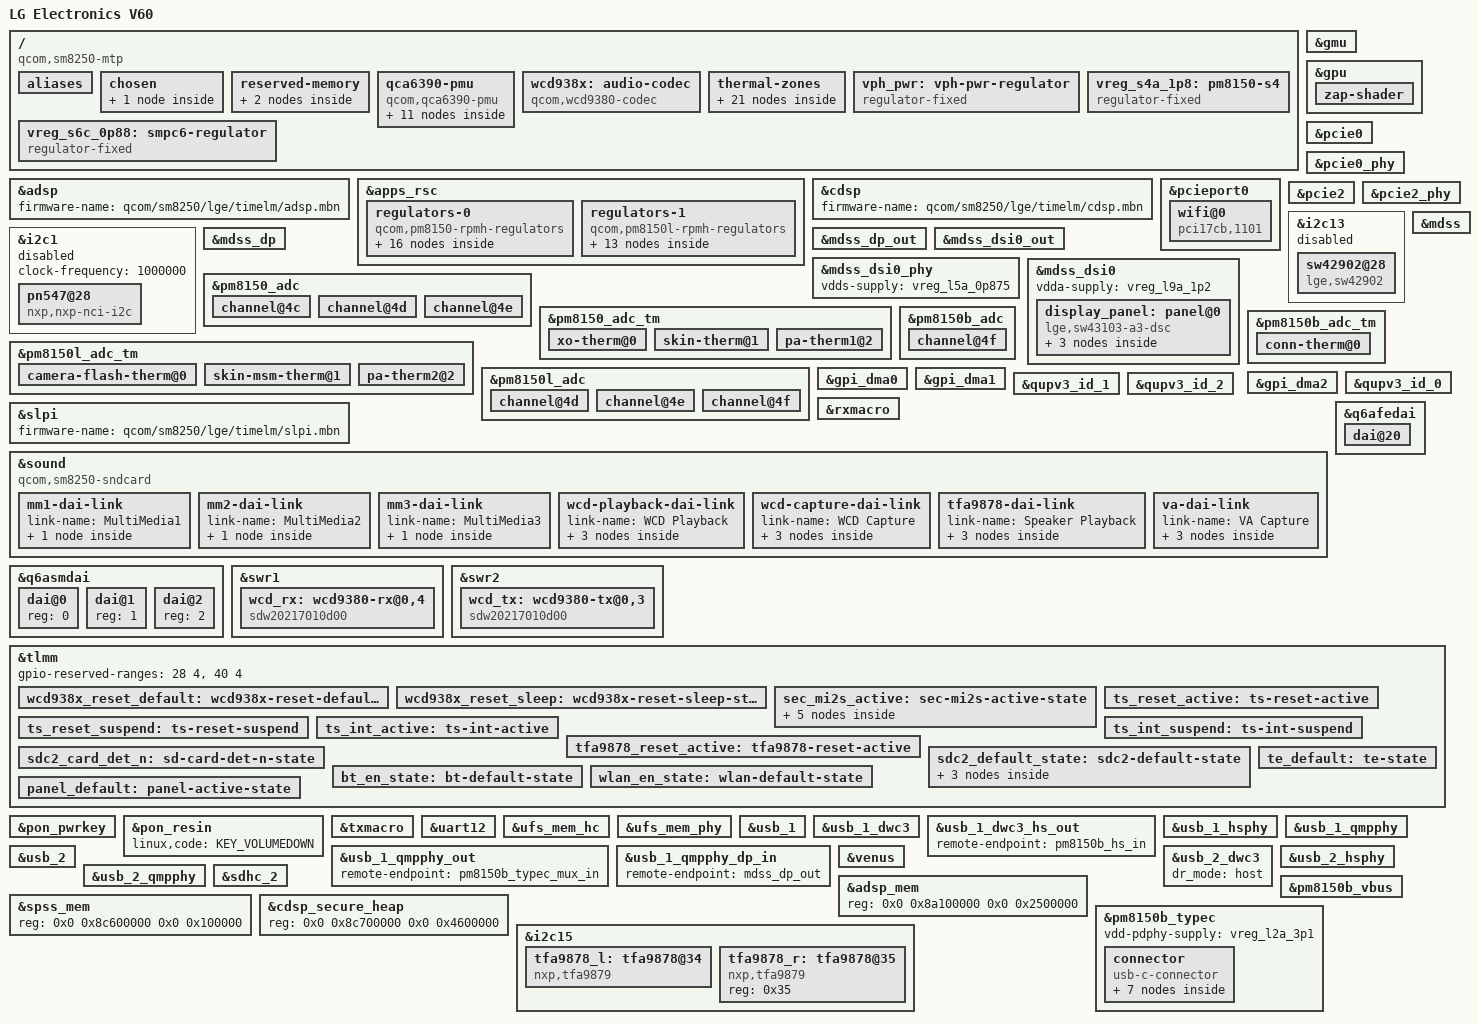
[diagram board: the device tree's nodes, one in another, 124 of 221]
// SPDX-License-Identifier: BSD-3-Clause
/*
 * Copyright (c) 2020, The Linux Foundation. All rights reserved.
 */

/dts-v1/;

#include <dt-bindings/regulator/qcom,rpmh-regulator.h>
#include <dt-bindings/sound/qcom,q6afe.h>
#include <dt-bindings/sound/qcom,q6asm.h>
#include <dt-bindings/usb/pd.h>
#include <dt-bindings/gpio/gpio.h>
#include "sm8250.dtsi"
#include "pm8150.dtsi"
#include "pm8150b.dtsi"
#include "pm8150l.dtsi"
// #include "pm8009.dtsi"
#include "pmk8002.dtsi"
#include "pmx55.dtsi"

/ {
	model = "LG Electronics V60";
	compatible = "qcom,sm8250-mtp", "qcom,sm8250";
	chassis-type = "handset";
	qcom,msm-id = <0x164 0x20001>;
	qcom,board-id = <0xc0008 0x0>;

	aliases {
		serial0 = &uart12;
        display0 = &framebuffer;
	};

	chosen {
		#address-cells = <2>;
		#size-cells = <2>;
		ranges;
		// stdout-path = "serial0:115200n8";
		stdout-path = "display0";
		bootargs = "panic=30 loglevel=7 pd_ignore_unused clk_ignore_unused console=ttyS0,115200 console=tty1 root=/dev/sda27 rw rootfs_part=sda27";

		framebuffer: framebuffer@9c000000 {
			compatible = "simple-framebuffer";
			reg = <0x0 0x9c000000 0x0 0x1200000>;
			width = <1080>;
			height = <2460>;
			stride = <(1080 * 4)>;
			format = "a8r8g8b8";
			/*
			 * That's a lot of clocks, but it's necessary due
			 * to unused clk cleanup & no panel driver yet..
			 */
			// clocks = <&dispcc DISP_CC_MDSS_AHB_CLK>,
			// 	 <&gcc GCC_DISP_HF_AXI_CLK>,
			// 	 <&gcc GCC_DISP_SF_AXI_CLK>,
			// 	 <&dispcc DISP_CC_MDSS_VSYNC_CLK>,
			// 	 <&dispcc DISP_CC_MDSS_MDP_CLK>,
			// 	 <&dispcc DISP_CC_MDSS_BYTE0_CLK>,
			// 	 <&dispcc DISP_CC_MDSS_BYTE0_INTF_CLK>,
			// 	 <&dispcc DISP_CC_MDSS_PCLK0_CLK>,
			// 	 <&dispcc DISP_CC_MDSS_ESC0_CLK>;
			// power-domains = <&dispcc MDSS_GDSC>;
		};
	};

	reserved-memory {
		ramoops_region@b0000000 {
			compatible = "removed-dma-pool";
			no-map;
			reg = <0x0 0xb0000000 0x0 0x300000>;
		};

		cont_splash_region@9c000000 {
			reg = <0x0 0x9c000000 0x0 0x1200000>;
			label = "cont_splash_region";
			no-map;
		};
	};

	qca6390-pmu {
		compatible = "qcom,qca6390-pmu";

		pinctrl-names = "default";
		pinctrl-0 = <&bt_en_state>, <&wlan_en_state>;

		vddaon-supply = <&vreg_s6a_0p95>;
		vddpmu-supply = <&vreg_s6a_0p95>;
		vddrfa0p95-supply = <&vreg_s6a_0p95>;
		vddrfa1p3-supply = <&vreg_s8c_1p3>;
		vddrfa1p9-supply = <&vreg_s5a_1p9>;
		vddpcie1p3-supply = <&vreg_s8c_1p3>;
		vddpcie1p9-supply = <&vreg_s5a_1p9>;
		vddio-supply = <&vreg_s4a_1p8>;

		wlan-enable-gpios = <&tlmm 20 GPIO_ACTIVE_HIGH>;
		bt-enable-gpios = <&tlmm 21 GPIO_ACTIVE_HIGH>;

		regulators {
			vreg_pmu_rfa_cmn: ldo0 {
				regulator-name = "vreg_pmu_rfa_cmn";
			};

			vreg_pmu_aon_0p59: ldo1 {
				regulator-name = "vreg_pmu_aon_0p59";
			};

			vreg_pmu_wlcx_0p8: ldo2 {
				regulator-name = "vreg_pmu_wlcx_0p8";
			};

			vreg_pmu_wlmx_0p85: ldo3 {
				regulator-name = "vreg_pmu_wlmx_0p85";
			};

			vreg_pmu_btcmx_0p85: ldo4 {
				regulator-name = "vreg_pmu_btcmx_0p85";
			};

			vreg_pmu_rfa_0p8: ldo5 {
				regulator-name = "vreg_pmu_rfa_0p8";
			};

			vreg_pmu_rfa_1p2: ldo6 {
				regulator-name = "vreg_pmu_rfa_1p2";
			};

			vreg_pmu_rfa_1p7: ldo7 {
				regulator-name = "vreg_pmu_rfa_1p7";
			};

			vreg_pmu_pcie_0p9: ldo8 {
				regulator-name = "vreg_pmu_pcie_0p9";
			};

			vreg_pmu_pcie_1p8: ldo9 {
				regulator-name = "vreg_pmu_pcie_1p8";
			};
		};
	};

	wcd938x: audio-codec {
		compatible = "qcom,wcd9380-codec";

		reset-gpios = <&tlmm 32 GPIO_ACTIVE_LOW>;

		vdd-buck-supply = <&vreg_s4a_1p8>;
		vdd-rxtx-supply = <&vreg_s4a_1p8>;
		vdd-io-supply = <&vreg_s4a_1p8>;
		vdd-mic-bias-supply = <&vreg_bob>;

		qcom,micbias1-microvolt = <1800000>;
		qcom,micbias2-microvolt = <1800000>;
		qcom,micbias3-microvolt = <1800000>;
		qcom,micbias4-microvolt = <1800000>;
		qcom,mbhc-buttons-vthreshold-microvolt = <75000 150000 237000 500000 500000 500000 500000 500000>;
		qcom,mbhc-headset-vthreshold-microvolt = <1700000>;
		qcom,mbhc-headphone-vthreshold-microvolt = <50000>;
		qcom,rx-device = <&wcd_rx>;
		qcom,tx-device = <&wcd_tx>;

		#sound-dai-cells = <1>;
	};

	thermal-zones {
		camera-thermal {
			thermal-sensors = <&pm8150l_adc_tm 0>;

			trips {
				active-config0 {
					temperature = <125000>;
					hysteresis = <1000>;
					type = "passive";
				};
			};
		};

		conn-thermal {
			thermal-sensors = <&pm8150b_adc_tm 0>;

			trips {
				active-config0 {
					temperature = <125000>;
					hysteresis = <1000>;
					type = "passive";
				};
			};
		};

		mmw-pa1-thermal {
			thermal-sensors = <&pm8150_adc_tm 2>;

			trips {
				active-config0 {
					temperature = <125000>;
					hysteresis = <1000>;
					type = "passive";
				};
			};
		};

		mmw-pa2-thermal {
			thermal-sensors = <&pm8150l_adc_tm 2>;

			trips {
				active-config0 {
					temperature = <125000>;
					hysteresis = <1000>;
					type = "passive";
				};
			};
		};

		skin-msm-thermal {
			thermal-sensors = <&pm8150l_adc_tm 1>;

			trips {
				active-config0 {
					temperature = <125000>;
					hysteresis = <1000>;
					type = "passive";
				};
			};
		};

		skin-thermal {
			thermal-sensors = <&pm8150_adc_tm 1>;

			trips {
				active-config0 {
					temperature = <125000>;
					hysteresis = <1000>;
					type = "passive";
				};
			};
		};

		xo-thermal {
			thermal-sensors = <&pm8150_adc_tm 0>;

			trips {
				active-config0 {
					temperature = <125000>;
					hysteresis = <1000>;
					type = "passive";
				};
			};
		};
	};

	vph_pwr: vph-pwr-regulator {
		compatible = "regulator-fixed";
		regulator-name = "vph_pwr";
		regulator-min-microvolt = <3700000>;
		regulator-max-microvolt = <3700000>;
	};

	vreg_s4a_1p8: pm8150-s4 {
		compatible = "regulator-fixed";
		regulator-name = "vreg_s4a_1p8";

		regulator-min-microvolt = <1800000>;
		regulator-max-microvolt = <1800000>;

		regulator-always-on;
		regulator-boot-on;

		vin-supply = <&vph_pwr>;
	};

	vreg_s6c_0p88: smpc6-regulator {
		compatible = "regulator-fixed";
		regulator-name = "vreg_s6c_0p88";

		regulator-min-microvolt = <880000>;
		regulator-max-microvolt = <880000>;
		regulator-always-on;
		vin-supply = <&vph_pwr>;
	};
};

&adsp {
	status = "okay";
	firmware-name = "qcom/sm8250/lge/timelm/adsp.mbn";
};

&apps_rsc {
	regulators-0 {
		compatible = "qcom,pm8150-rpmh-regulators";
		qcom,pmic-id = "a";

		vdd-s1-supply = <&vph_pwr>;
		vdd-s2-supply = <&vph_pwr>;
		vdd-s3-supply = <&vph_pwr>;
		vdd-s4-supply = <&vph_pwr>;
		vdd-s5-supply = <&vph_pwr>;
		vdd-s6-supply = <&vph_pwr>;
		vdd-s7-supply = <&vph_pwr>;
		vdd-s8-supply = <&vph_pwr>;
		vdd-s9-supply = <&vph_pwr>;
		vdd-s10-supply = <&vph_pwr>;
		vdd-l1-l8-l11-supply = <&vreg_s6c_0p88>;
		vdd-l2-l10-supply = <&vreg_bob>;
		vdd-l3-l4-l5-l18-supply = <&vreg_s6a_0p95>;
		vdd-l6-l9-supply = <&vreg_s8c_1p3>;
		vdd-l7-l12-l14-l15-supply = <&vreg_s5a_1p9>;
		vdd-l13-l16-l17-supply = <&vreg_bob>;

		vreg_s5a_1p9: smps5 {
			regulator-name = "vreg_s5a_1p9";
			regulator-min-microvolt = <1904000>;
			regulator-max-microvolt = <2000000>;
			regulator-initial-mode = <RPMH_REGULATOR_MODE_HPM>;
		};

		vreg_s6a_0p95: smps6 {
			regulator-name = "vreg_s6a_0p95";
			regulator-min-microvolt = <920000>;
			regulator-max-microvolt = <1128000>;
			regulator-initial-mode = <RPMH_REGULATOR_MODE_HPM>;
		};

		vreg_l2a_3p1: ldo2 {
			regulator-name = "vreg_l2a_3p1";
			regulator-min-microvolt = <3072000>;
			regulator-max-microvolt = <3072000>;
			regulator-initial-mode = <RPMH_REGULATOR_MODE_HPM>;
		};

		vreg_l3a_0p9: ldo3 {
			regulator-name = "vreg_l3a_0p9";
			regulator-min-microvolt = <928000>;
			regulator-max-microvolt = <932000>;
			regulator-initial-mode = <RPMH_REGULATOR_MODE_HPM>;
		};

		vreg_l5a_0p875: ldo5 {
			regulator-name = "vreg_l5a_0p875";
			regulator-min-microvolt = <880000>;
			regulator-max-microvolt = <880000>;
			regulator-initial-mode = <RPMH_REGULATOR_MODE_HPM>;
		};

		vreg_l6a_1p2: ldo6 {
			regulator-name = "vreg_l6a_1p2";
			regulator-min-microvolt = <1200000>;
			regulator-max-microvolt = <1200000>;
			regulator-initial-mode = <RPMH_REGULATOR_MODE_HPM>;
		};

		vreg_l7a_1p7: ldo7 {
			regulator-name = "vreg_l7a_1p7";
			regulator-min-microvolt = <1704000>;
			regulator-max-microvolt = <1800000>;
			regulator-initial-mode = <RPMH_REGULATOR_MODE_HPM>;
		};

		vreg_l9a_1p2: ldo9 {
			regulator-name = "vreg_l9a_1p2";
			regulator-min-microvolt = <1200000>;
			regulator-max-microvolt = <1200000>;
			regulator-initial-mode = <RPMH_REGULATOR_MODE_HPM>;
		};

		vreg_l10a_1p8: ldo10 {
			regulator-name = "vreg_l10a_1p8";
			regulator-min-microvolt = <1800000>;
			regulator-max-microvolt = <1800000>;
			regulator-initial-mode = <RPMH_REGULATOR_MODE_HPM>;
		};

		vreg_l12a_1p8: ldo12 {
			regulator-name = "vreg_l12a_1p8";
			regulator-min-microvolt = <1800000>;
			regulator-max-microvolt = <1800000>;
			regulator-initial-mode = <RPMH_REGULATOR_MODE_HPM>;
		};

		vreg_l13a_ts_3p0: ldo13 {
			regulator-name = "vreg_l13a_ts_3p0";
			regulator-min-microvolt = <3008000>;
			regulator-max-microvolt = <3008000>;
			regulator-initial-mode = <RPMH_REGULATOR_MODE_HPM>;
		};

		vreg_l14a_1p8: ldo14 {
			regulator-name = "vreg_l14a_1p8";
			regulator-min-microvolt = <1800000>;
			regulator-max-microvolt = <1880000>;
			regulator-initial-mode = <RPMH_REGULATOR_MODE_HPM>;
		};

		vreg_l15a_11ad_io_1p8: ldo15 {
			regulator-name = "vreg_l15a_11ad_io_1p8";
			regulator-min-microvolt = <1800000>;
			regulator-max-microvolt = <1800000>;
			regulator-initial-mode = <RPMH_REGULATOR_MODE_HPM>;
		};

		vreg_l16a_2p7: ldo16 {
			regulator-name = "vreg_l16a_2p7";
			regulator-min-microvolt = <2704000>;
			regulator-max-microvolt = <2960000>;
			regulator-initial-mode = <RPMH_REGULATOR_MODE_HPM>;
		};

		vreg_l17a_3p0: ldo17 {
			regulator-name = "vreg_l17a_3p0";
			regulator-min-microvolt = <2856000>;
			regulator-max-microvolt = <3008000>;
			regulator-initial-mode = <RPMH_REGULATOR_MODE_HPM>;
		};

		vreg_l18a_0p9: ldo18 {
			regulator-name = "vreg_l18a_0p9";
			regulator-min-microvolt = <912000>;
			regulator-max-microvolt = <912000>;
			regulator-initial-mode = <RPMH_REGULATOR_MODE_HPM>;
		};
	};

	regulators-1 {
		compatible = "qcom,pm8150l-rpmh-regulators";
		qcom,pmic-id = "c";

		vdd-s1-supply = <&vph_pwr>;
		vdd-s2-supply = <&vph_pwr>;
		vdd-s3-supply = <&vph_pwr>;
		vdd-s4-supply = <&vph_pwr>;
		vdd-s5-supply = <&vph_pwr>;
		vdd-s6-supply = <&vph_pwr>;
		vdd-s7-supply = <&vph_pwr>;
		vdd-s8-supply = <&vph_pwr>;
		vdd-l1-l8-supply = <&vreg_s4a_1p8>;
		vdd-l2-l3-supply = <&vreg_s8c_1p3>;
		vdd-l4-l5-l6-supply = <&vreg_bob>;
		vdd-l7-l11-supply = <&vreg_bob>;
		vdd-l9-l10-supply = <&vreg_bob>;
		vdd-bob-supply = <&vph_pwr>;

		vreg_bob: bob {
			regulator-name = "vreg_bob";
			regulator-min-microvolt = <3008000>;
			regulator-max-microvolt = <4000000>;
			regulator-initial-mode = <RPMH_REGULATOR_MODE_AUTO>;
		};

		vreg_s8c_1p3: smps8 {
			regulator-name = "vreg_s8c_1p3";
			regulator-min-microvolt = <1352000>;
			regulator-max-microvolt = <1352000>;
			regulator-initial-mode = <RPMH_REGULATOR_MODE_HPM>;
		};

		vreg_l1c_1p8: ldo1 {
			regulator-name = "vreg_l1c_1p8";
			regulator-min-microvolt = <1800000>;
			regulator-max-microvolt = <1800000>;
			regulator-initial-mode = <RPMH_REGULATOR_MODE_HPM>;
		};

		vreg_l2c_1p2: ldo2 {
			regulator-name = "vreg_l2c_1p2";
			regulator-min-microvolt = <1200000>;
			regulator-max-microvolt = <1200000>;
			regulator-initial-mode = <RPMH_REGULATOR_MODE_HPM>;
		};

		vreg_l3c_0p92: ldo3 {
			regulator-name = "vreg_l3c_0p92";
			regulator-min-microvolt = <920000>;
			regulator-max-microvolt = <920000>;
			regulator-initial-mode = <RPMH_REGULATOR_MODE_HPM>;
		};

		vreg_l4c_1p7: ldo4 {
			regulator-name = "vreg_l4c_1p7";
			regulator-min-microvolt = <1704000>;
			regulator-max-microvolt = <2928000>;
			regulator-initial-mode = <RPMH_REGULATOR_MODE_HPM>;
		};

		vreg_l5c_1p8: ldo5 {
			regulator-name = "vreg_l5c_1p8";
			regulator-min-microvolt = <1800000>;
			regulator-max-microvolt = <2928000>;
			regulator-initial-mode = <RPMH_REGULATOR_MODE_HPM>;
		};

		vreg_l6c_2p9: ldo6 {
			regulator-name = "vreg_l6c_2p9";
			regulator-min-microvolt = <1800000>;
			regulator-max-microvolt = <2960000>;
			regulator-initial-mode = <RPMH_REGULATOR_MODE_HPM>;
		};

		vreg_l7c_cam_vcm0_2p85: ldo7 {
			regulator-name = "vreg_l7c_cam_vcm0_2p85";
			regulator-min-microvolt = <2856000>;
			regulator-max-microvolt = <3104000>;
			regulator-initial-mode = <RPMH_REGULATOR_MODE_HPM>;
		};

		vreg_l8c_1p8: ldo8 {
			regulator-name = "vreg_l8c_1p8";
			regulator-min-microvolt = <1800000>;
			regulator-max-microvolt = <1800000>;
			regulator-initial-mode = <RPMH_REGULATOR_MODE_HPM>;
		};

		vreg_l9c_2p9: ldo9 {
			regulator-name = "vreg_l9c_2p9";
			regulator-min-microvolt = <2704000>;
			regulator-max-microvolt = <2960000>;
			regulator-initial-mode = <RPMH_REGULATOR_MODE_HPM>;
		};

		vreg_l10c_3p0: ldo10 {
			regulator-name = "vreg_l10c_3p0";
			regulator-min-microvolt = <3000000>;
			regulator-max-microvolt = <3000000>;
			regulator-initial-mode = <RPMH_REGULATOR_MODE_HPM>;
		};

		vreg_l11c_3p3: ldo11 {
			regulator-name = "vreg_l11c_3p3";
			regulator-min-microvolt = <3000000>;
			regulator-max-microvolt = <3312000>;
			regulator-initial-mode = <RPMH_REGULATOR_MODE_HPM>;
		};
	};
};

&cdsp {
	status = "okay";
	firmware-name = "qcom/sm8250/lge/timelm/cdsp.mbn";
};

&gmu {
	status = "okay";
};

&gpu {
	status = "okay";

	zap-shader {
		memory-region = <&gpu_mem>;
		firmware-name = "qcom/sm8250/lge/timelm/a650_zap.mbn";
	};
};

&pcie0 {
	status = "okay";
};

&pcie0_phy {
	status = "okay";
	vdda-phy-supply = <&vreg_l5a_0p875>;
	vdda-pll-supply = <&vreg_l9a_1p2>;
};

&pcieport0 {
	wifi@0 {
		compatible = "pci17cb,1101";
		reg = <0x10000 0x0 0x0 0x0 0x0>;

		vddrfacmn-supply = <&vreg_pmu_rfa_cmn>;
		vddaon-supply = <&vreg_pmu_aon_0p59>;
		vddwlcx-supply = <&vreg_pmu_wlcx_0p8>;
		vddwlmx-supply = <&vreg_pmu_wlmx_0p85>;
		vddrfa0p8-supply = <&vreg_pmu_rfa_0p8>;
		vddrfa1p2-supply = <&vreg_pmu_rfa_1p2>;
		vddrfa1p7-supply = <&vreg_pmu_rfa_1p7>;
		vddpcie0p9-supply = <&vreg_pmu_pcie_0p9>;
		vddpcie1p8-supply = <&vreg_pmu_pcie_1p8>;
	};
};

&pcie2 {
	status = "okay";
};

&pcie2_phy {
	status = "okay";
	vdda-phy-supply = <&vreg_l5a_0p875>;
	vdda-pll-supply = <&vreg_l9a_1p2>;
};

&i2c1 {
	status = "disabled";
	clock-frequency = <1000000>;
	
	pn547@28 {
		compatible = "nxp,nxp-nci-i2c";
		status = "okay";
		reg = <0x28>;
		interrupt-parent = <&tlmm>;
		interrupts = <111 IRQ_TYPE_LEVEL_HIGH>;
		enable-gpios = <&tlmm 6 GPIO_ACTIVE_HIGH>;
		firmware-gpios = <&tlmm 110 GPIO_ACTIVE_HIGH>;
	};
};

&i2c13 {
	status = "disabled";
	sw42902@28 {
		compatible = "lge,sw42902";
		reg = <0x28>;
		status = "okay";
		interrupt-parent = <&tlmm>;
		interrupts = <39 0x2008>; /* IRQF_ONESHOT|IRQF_TRIGGER_LOW */
		irqflags = <2>; /* IRQF_TRIGGER_FALLING */

		vdd-gpio = <&tlmm 68 0>;
		vcl-gpio = <&tlmm 67 0>;
		reset-gpio = <&tlmm 38 0>;
		irq-gpio = <&tlmm 39 0x2008>; /* IRQF_ONESHOT|IRQF_TRIGGER_LOW */

		/* caps */
		max_x = <1080>;
		max_y = <2460>;
		max_pressure = <255>;
		max_width_major = <2460>;
		max_width_minor = <2460>;
		max_orientation = <90>;
		max_id = <10>;
		hw_reset_delay = <90>;
		sw_reset_delay = <10>;

		/* role */
		use_lpwg = <1>;
		use_lpwg_test = <1>;
		hide_coordinate = <1>;
		use_activepen_status = <1>;
		use_film_status = <1>;
		use_dex_mode = <1>;

		/* firmware */
		fw_image = "touch/timelm/B3W68TIME_0_74.img",
			   "touch/timelm/B3W68DS3_0_16.img";

		/* asc */
		use_asc = <0>;
		low_delta_thres = <350>;
		high_delta_thres = <600>;
		max_delta_cnt = <2>;

		/* Performance Test */
		use_perf_test = <1>;
		test_delay = <8>;
		test_pressure = <50>;
		test_width = <100>;
		click_test_x = <180>;
		click_test_y = <760>;
		v_drag_test_x = <144>;
		v_drag_test_start_y = <2003>;
		v_drag_test_end_y = <1116>;
		h_drag_test_start_x = <1163>;
		h_drag_test_end_x = <276>;
		h_drag_test_y = <2184>;
	};
};

&mdss {
	status = "okay";
};

&mdss_dp {
	status = "okay";
};

&mdss_dp_out {
	data-lanes = <0 1>;
	remote-endpoint = <&usb_1_qmpphy_dp_in>;
};

&mdss_dsi0_out {
	remote-endpoint = <&panel_in_0>;
	data-lanes = <0 1 2 3>;
};

&mdss_dsi0_phy {
	vdds-supply = <&vreg_l5a_0p875>;
	status = "okay";
};

&mdss_dsi0 {
	vdda-supply = <&vreg_l9a_1p2>;
	status = "okay";

	display_panel: panel@0 {
		reg = <0>;
		compatible = "lge,sw43103-a3-dsc";
		vddio-supply = <&vreg_l14a_1p8>;
		reset-gpios = <&tlmm 75 GPIO_ACTIVE_LOW>;

		pinctrl-names = "default";
		pinctrl-0 = <&panel_default>, <&te_default>;

		status = "okay";

		ports {
			#address-cells = <1>;
			#size-cells = <0>;

			port@0 {
				reg = <0>;

				panel_in_0: endpoint {
					remote-endpoint = <&mdss_dsi0_out>;
				};
			};
		};
	};
};

&pm8150_adc {
	channel@4c {
		reg = <ADC5_XO_THERM_100K_PU>;
		qcom,ratiometric;
		qcom,hw-settle-time = <200>;
		label = "xo_therm";
	};

	channel@4d {
		reg = <ADC5_AMUX_THM1_100K_PU>;
		qcom,ratiometric;
		qcom,hw-settle-time = <200>;
		label = "skin_therm";
	};

	channel@4e {
		reg = <ADC5_AMUX_THM2_100K_PU>;
		qcom,ratiometric;
		qcom,hw-settle-time = <200>;
		label = "pa_therm1";
	};
};

&pm8150_adc_tm {
	status = "okay";

	xo-therm@0 {
		reg = <0>;
		io-channels = <&pm8150_adc ADC5_XO_THERM_100K_PU>;
		qcom,ratiometric;
		qcom,hw-settle-time-us = <200>;
	};

	skin-therm@1 {
		reg = <1>;
		io-channels = <&pm8150_adc ADC5_AMUX_THM1_100K_PU>;
		qcom,ratiometric;
		qcom,hw-settle-time-us = <200>;
	};

	pa-therm1@2 {
		reg = <2>;
		io-channels = <&pm8150_adc ADC5_AMUX_THM2_100K_PU>;
		qcom,ratiometric;
		qcom,hw-settle-time-us = <200>;
	};
};

&pm8150b_adc {
	channel@4f {
		reg = <ADC5_AMUX_THM3_100K_PU>;
		qcom,ratiometric;
		qcom,hw-settle-time = <200>;
		label = "conn_therm";
	};
};

&pm8150b_adc_tm {
	status = "okay";

	conn-therm@0 {
		reg = <0>;
		io-channels = <&pm8150b_adc ADC5_AMUX_THM3_100K_PU>;
		qcom,ratiometric;
		qcom,hw-settle-time-us = <200>;
	};
};

&pm8150l_adc_tm {
	status = "okay";

	camera-flash-therm@0 {
		reg = <0>;
		io-channels = <&pm8150l_adc ADC5_AMUX_THM1_100K_PU>;
		qcom,ratiometric;
		qcom,hw-settle-time-us = <200>;
	};

	skin-msm-therm@1 {
		reg = <1>;
		io-channels = <&pm8150l_adc ADC5_AMUX_THM2_100K_PU>;
		qcom,ratiometric;
		qcom,hw-settle-time-us = <200>;
	};

	pa-therm2@2 {
		reg = <2>;
		io-channels = <&pm8150l_adc ADC5_AMUX_THM3_100K_PU>;
		qcom,ratiometric;
		qcom,hw-settle-time-us = <200>;
	};
};

&pm8150l_adc {
	channel@4d {
		reg = <ADC5_AMUX_THM1_100K_PU>;
		qcom,ratiometric;
		qcom,hw-settle-time = <200>;
		label = "camera_flash_therm";
	};

	channel@4e {
		reg = <ADC5_AMUX_THM2_100K_PU>;
		qcom,ratiometric;
		qcom,hw-settle-time = <200>;
		label = "skin_msm_therm";
	};

	channel@4f {
		reg = <ADC5_AMUX_THM3_100K_PU>;
		qcom,ratiometric;
		qcom,hw-settle-time = <200>;
		label = "pa_therm2";
	};
};

&gpi_dma0 {
	status = "okay";
};

&gpi_dma1 {
	status = "okay";
};

&gpi_dma2 {
	status = "okay";
};

&qupv3_id_0 {
	status = "okay";
};

&qupv3_id_1 {
	status = "okay";
};

&qupv3_id_2 {
	status = "okay";
};

&rxmacro {
	status = "okay";
};

&slpi {
	status = "okay";
	firmware-name = "qcom/sm8250/lge/timelm/slpi.mbn";
};

&sound {
	compatible = "qcom,sm8250-sndcard";
	pinctrl-0 = <&sec_mi2s_active>;
	pinctrl-names = "default";
	model = "SM8250-MTP-WCD9380-TFA9878-VA-DMIC";
	audio-routing =
		"IN1_HPHL", "HPHL_OUT",
		"IN2_HPHR", "HPHR_OUT",
		"AMIC1", "MIC BIAS1",
		"AMIC2", "MIC BIAS2",
		"AMIC3", "MIC BIAS3",
		"AMIC4", "MIC BIAS3",
		"AMIC5", "MIC BIAS4";

	mm1-dai-link {
		link-name = "MultiMedia1";
		cpu {
			sound-dai = <&q6asmdai  MSM_FRONTEND_DAI_MULTIMEDIA1>;
		};
	};

	mm2-dai-link {
		link-name = "MultiMedia2";
		cpu {
			sound-dai = <&q6asmdai  MSM_FRONTEND_DAI_MULTIMEDIA2>;
		};
	};

	mm3-dai-link {
		link-name = "MultiMedia3";
		cpu {
			sound-dai = <&q6asmdai  MSM_FRONTEND_DAI_MULTIMEDIA3>;
		};
	};

	wcd-playback-dai-link {
		link-name = "WCD Playback";
		cpu {
			sound-dai = <&q6afedai RX_CODEC_DMA_RX_0>;
		};
		codec {
			sound-dai = <&wcd938x 0>, <&swr1 0>, <&rxmacro 0>;
		};
		platform {
			sound-dai = <&q6routing>;
		};
	};

	wcd-capture-dai-link {
		link-name = "WCD Capture";
		cpu {
			sound-dai = <&q6afedai TX_CODEC_DMA_TX_3>;
		};

		codec {
			sound-dai = <&wcd938x 1>, <&swr2 0>, <&txmacro 0>;
		};
		platform {
			sound-dai = <&q6routing>;
		};
	};
	
	tfa9878-dai-link {
		link-name = "Speaker Playback";
		cpu {
			sound-dai = <&q6afedai SECONDARY_MI2S_RX>;
		};

		platform {
			sound-dai = <&q6routing>;
		};

		codec {
			sound-dai = <&tfa9878_l 0>, <&tfa9878_r 0>;
		};
	};

	va-dai-link {
		link-name = "VA Capture";
		cpu {
			sound-dai = <&q6afedai VA_CODEC_DMA_TX_0>;
		};

		platform {
			sound-dai = <&q6routing>;
		};

		codec {
			sound-dai = <&vamacro 0>;
		};
	};
};

&q6afedai {
	dai@20 {
		reg = <SECONDARY_MI2S_RX>;
		qcom,sd-lines = <0>;
	};
};

&q6asmdai {
	dai@0 {
		reg = <0>;
	};

	dai@1 {
		reg = <1>;
	};

	dai@2 {
		reg = <2>;
	};
};


&swr1 {
	status = "okay";

	wcd_rx: wcd9380-rx@0,4 {
		compatible = "sdw20217010d00";
		reg = <0 4>;
		qcom,rx-port-mapping = <1 2 3 4 5>;
	};
};

&swr2 {
	status = "okay";

	wcd_tx: wcd9380-tx@0,3 {
		compatible = "sdw20217010d00";
		reg = <0 3>;
		qcom,tx-port-mapping = <2 3 4 5>;
	};
};

&tlmm {
	gpio-reserved-ranges = <28 4>, <40 4>;

	wcd938x_reset_default: wcd938x-reset-default-state {
		pins = "gpio32";
		function = "gpio";
		drive-strength = <16>;
		output-high;
	};

	wcd938x_reset_sleep: wcd938x-reset-sleep-state {
		pins = "gpio32";
		function = "gpio";
		drive-strength = <16>;
		bias-disable;
		output-low;
	};

	sec_mi2s_active: sec-mi2s-active-state {
		mclk-pins {
			pins = "gpio137";
			function = "sec_mi2s";
			drive-strength = <8>;
			bias-disable;
		};

		sck-pins {
			pins = "gpio142";
			function = "mi2s1_sck";
			drive-strength = <8>;
			bias-disable;
		};

		data0-pins {
			pins = "gpio143";
			function = "mi2s1_data0";
			drive-strength = <8>;
			bias-disable;
		};
		
		data1-pins {
			pins = "gpio144";
			function = "mi2s1_data1";
			drive-strength = <8>;
			bias-disable;
		};

		ws-pins {
			pins = "gpio145";
			function = "mi2s1_ws";
			drive-strength = <8>;
			output-high;
		};
	};

	ts_reset_active: ts-reset-active {
		pins = "gpio38";
		function = "gpio";
		drive-strength = <6>;
		output-high;
	};

	ts_reset_suspend: ts-reset-suspend {
		pins = "gpio38";
		function = "gpio";
		drive-strength = <6>;
		bias-disable;
		output-low;
	};

	ts_int_active: ts-int-active {
		pins = "gpio39";
		function = "gpio";
		drive-strength = <2>;
		bias-pull-up;
	};

	ts_int_suspend: ts-int-suspend {
		pins = "gpio39";
		function = "gpio";
		drive-strength = <2>;
		bias-disable;
	};
	
	tfa9878_reset_active: tfa9878-reset-active {
		pins = "gpio99";
		function = "gpio";
		drive-strength = <2>;
		output-high;
	};

	sdc2_card_det_n: sd-card-det-n-state {
		pins = "gpio77";
		function = "gpio";
		bias-pull-up;
		drive-strength = <2>;
	};

	sdc2_default_state: sdc2-default-state {
		clk-pins {
			pins = "sdc2_clk";
			drive-strength = <16>;
			bias-disable;
		};

		cmd-pins {
			pins = "sdc2_cmd";
			drive-strength = <10>;
			bias-pull-up;
		};

		data-pins {
			pins = "sdc2_data";
			drive-strength = <10>;
			bias-pull-up;
		};
	};
	
	bt_en_state: bt-default-state {
		pins = "gpio21";
		function = "gpio";
		drive-strength = <16>;
		output-low;
		bias-pull-up;
	};

	wlan_en_state: wlan-default-state {
		pins = "gpio20";
		function = "gpio";
		drive-strength = <16>;
		output-low;
		bias-pull-up;
	};

	panel_default: panel-active-state {
		pins = "gpio75";
		function = "gpio";
		drive-strength = <8>;
		bias-disable;
	};

	te_default: te-state {
		pins = "gpio66";
		function = "mdp_vsync";
		drive-strength = <2>;
		bias-pull-down;
	};
};

&pon_pwrkey {
	status = "okay";
};

&pon_resin {
	status = "okay";
	linux,code = <KEY_VOLUMEDOWN>;
};

&txmacro {
	status = "okay";
};

&uart12 {
	status = "okay";
};

&ufs_mem_hc {
	status = "okay";

	vcc-supply = <&vreg_l17a_3p0>;
	vcc-max-microamp = <800000>;
	vccq-supply = <&vreg_l6a_1p2>;
	vccq-max-microamp = <800000>;
	vccq2-supply = <&vreg_s4a_1p8>;
	vccq2-max-microamp = <800000>;
};

&ufs_mem_phy {
	status = "okay";

	vdda-phy-supply = <&vreg_l5a_0p875>;
	vdda-pll-supply = <&vreg_l9a_1p2>;
};

&usb_1 {
	status = "okay";
};

&usb_1_dwc3 {
	dr_mode = "otg";
	usb-role-switch;
};

&usb_1_dwc3_hs_out {
	remote-endpoint = <&pm8150b_hs_in>;
};

&usb_1_hsphy {
	status = "okay";

	vdda-pll-supply = <&vreg_l5a_0p875>;
	vdda18-supply = <&vreg_l12a_1p8>;
	vdda33-supply = <&vreg_l2a_3p1>;
};

&usb_1_qmpphy {
	status = "okay";

	vdda-phy-supply = <&vreg_l9a_1p2>;
	vdda-pll-supply = <&vreg_l18a_0p9>;
};

&usb_1_qmpphy_out {
	remote-endpoint = <&pm8150b_typec_mux_in>;
};

&usb_1_qmpphy_dp_in {
	remote-endpoint = <&mdss_dp_out>;
};

&usb_2 {
	status = "okay";
};

&usb_2_dwc3 {
	dr_mode = "host";
};

&usb_2_hsphy {
	status = "okay";

	vdda-pll-supply = <&vreg_l5a_0p875>;
	vdda18-supply = <&vreg_l12a_1p8>;
	vdda33-supply = <&vreg_l2a_3p1>;
};

&usb_2_qmpphy {
	status = "okay";

	vdda-phy-supply = <&vreg_l9a_1p2>;
	vdda-pll-supply = <&vreg_l18a_0p9>;
};

&venus {
	status = "okay";
	firmware-name = "qcom/sm8250/lge/timelm/venus.mbn";
};

&sdhc_2 {
	status = "okay";
	cd-gpios = <&tlmm 77 GPIO_ACTIVE_LOW>;
	pinctrl-names = "default", "sleep";
	pinctrl-0 = <&sdc2_default_state &sdc2_card_det_n>;
	pinctrl-1 = <&sdc2_sleep_state &sdc2_card_det_n>;
	vmmc-supply = <&vreg_l9c_2p9>;
	vqmmc-supply = <&vreg_l6c_2p9>;
	bus-width = <4>;
	no-sdio;
	no-mmc;
};

&adsp_mem {
	reg = <0x0 0x8a100000 0x0 0x2500000>;
};

&spss_mem {
	reg = <0x0 0x8c600000 0x0 0x100000>;
};

&cdsp_secure_heap {
	reg = <0x0 0x8c700000 0x0 0x4600000>;
};

&pm8150b_vbus {
	regulator-min-microamp = <500000>;
	regulator-max-microamp = <3000000>;
	status = "okay";
};

&i2c15 {
	status = "okay";

	tfa9878_l: tfa9878@34 {
		compatible = "nxp,tfa9879";
		reg = <0x34>;
		pinctrl-names = "default";
		pinctrl-0 = <&tfa9878_reset_active>;
		#sound-dai-cells = <0>;
	};
	
	tfa9878_r: tfa9878@35 {
		compatible = "nxp,tfa9879";
		reg = <0x35>;
		#sound-dai-cells = <0>;
	};
};

&pm8150b_typec {
	status = "okay";

	vdd-pdphy-supply = <&vreg_l2a_3p1>;

	connector {
		compatible = "usb-c-connector";
		label = "USB-C";

		power-role = "source";
		data-role = "dual";
		self-powered;
		accessory-mode-audio = <1>;

		source-pdos = <PDO_FIXED(5000, 3000,
					 PDO_FIXED_DUAL_ROLE |
					 PDO_FIXED_USB_COMM |
					 PDO_FIXED_DATA_SWAP)>;

		altmodes {
			displayport {
				svid = /bits/ 16 <0xff01>;
				vdo = <0x00001c46>;
			};
		};

		ports {
			#address-cells = <1>;
			#size-cells = <0>;

			port@0 {
				reg = <0>;
				pm8150b_hs_in: endpoint {
					remote-endpoint = <&usb_1_dwc3_hs_out>;
				};
			};

			port@1 {
				reg = <1>;
				pm8150b_typec_mux_in: endpoint {
					remote-endpoint = <&usb_1_qmpphy_out>;
				};
			};
		};
	};
};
